AUTOSAR XML (schema 00054)
package /System
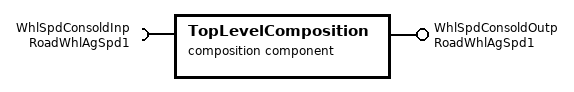
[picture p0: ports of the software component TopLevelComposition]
  composition sw component type TopLevelComposition
    require port WhlSpdConsoldInp: required-interface=RoadWhlAgSpd1
    provide port WhlSpdConsoldOutp: provided-interface=RoadWhlAgSpd1
    component CPT_VehicleSpeedComposition: type=VehicleSpeedComposition
    component CPT_WheelSpeedComposition: type=WheelSpeedComposition
    connect CPT_WheelSpeedComposition.WhlSpdConsoldOutp -> CPT_VehicleSpeedComposition.WhlSpdConsoldInp
    delegate CPT_WheelSpeedComposition.WhlSpdConsoldOutp <-> outer port TopLevelComposition/WhlSpdConsoldOutp
    delegate CPT_VehicleSpeedComposition.WhlSpdConsoldInp <-> outer port TopLevelComposition/WhlSpdConsoldInp
package /Systems
  system PF_System: category=SYSTEM_DESCRIPTION, ecu-extract-version=1.0.0, system-version=1.0.0
    system mapping SystemMapping
      data-mappings:
        data-element=RootSwCompositionPrototype.WhlSpdConsoldInp.RoadWhlAgSpd, system-signal=SysSig_EcuVehSpd_RoadWhlAgSpd_Rx
        data-element=RootSwCompositionPrototype.WhlSpdConsoldOutp.RoadWhlAgSpd, system-signal=SysSig_EcuWhlSpd_RoadWhlAgSpd_Tx
      sw-mappings:
        swc to ecu mapping SWcToECUMapping_VehSpd: component=RootSwCompositionPrototype.CPT_VehicleSpeedComposition, ecu-instance=VehicleSpeed, processing-unit=VehicleSpeed
        swc to ecu mapping SWcToECUMapping_WhlSpd: component=RootSwCompositionPrototype.CPT_WheelSpeedComposition, ecu-instance=WheelSpeed, processing-unit=WheelSpeed
    root-software-compositions:
      root sw composition prototype RootSwCompositionPrototype: software-composition=TopLevelComposition
package /SwComponentTypes
  composition sw component type WheelSpeedComposition
    provide port WhlSpdConsoldOutp: provided-interface=RoadWhlAgSpd1
    component CPT_WhlSpdSnsr: type=WhlSpdSnsr
    component CPT_WhlSpdVirt: type=WhlSpdVirt
    connect CPT_WhlSpdVirt.WhlSpdMeasdOutp -> CPT_WhlSpdSnsr.WhlSpdMeasdInp
    delegate CPT_WhlSpdSnsr.WhlSpdConsoldOutp <-> outer port WheelSpeedComposition/WhlSpdConsoldOutp
  composition sw component type VehicleSpeedComposition
    require port WhlSpdConsoldInp: required-interface=RoadWhlAgSpd1
    component CPT_VehSpdCalc: type=VehSpdCalc
    component CPT_VehSpdActr: type=VehSpdActr
    component CPT_VehSpdVirt: type=VehSpdVirt
    delegate CPT_VehSpdCalc.WhlSpdConsoldInp <-> outer port VehicleSpeedComposition/WhlSpdConsoldInp
    connect CPT_VehSpdActr.Led0CmdOutp -> CPT_VehSpdVirt.Led0CmdInp
    connect CPT_VehSpdActr.Led1CmdOutp -> CPT_VehSpdVirt.Led1CmdInp
    connect CPT_VehSpdCalc.VehSpdOutp -> CPT_VehSpdActr.VehSpdInp
package /CommunicationClusters
  can cluster CanCluster: protocol-name=CAN
    can physical channel CanPhysicalChannel: comm-connectors=[WhlSpd_CanConnector, VehSpd_CanConnector]
      frame CanFrame_EcuWhlSpd_RoadWhlAgSpd_Tx: id 0x100, can-addressing-mode=STANDARD
      frame CanFrame_EcuVehSpd_RoadWhlAgSpd_Rx: id 0x100, can-addressing-mode=STANDARD
